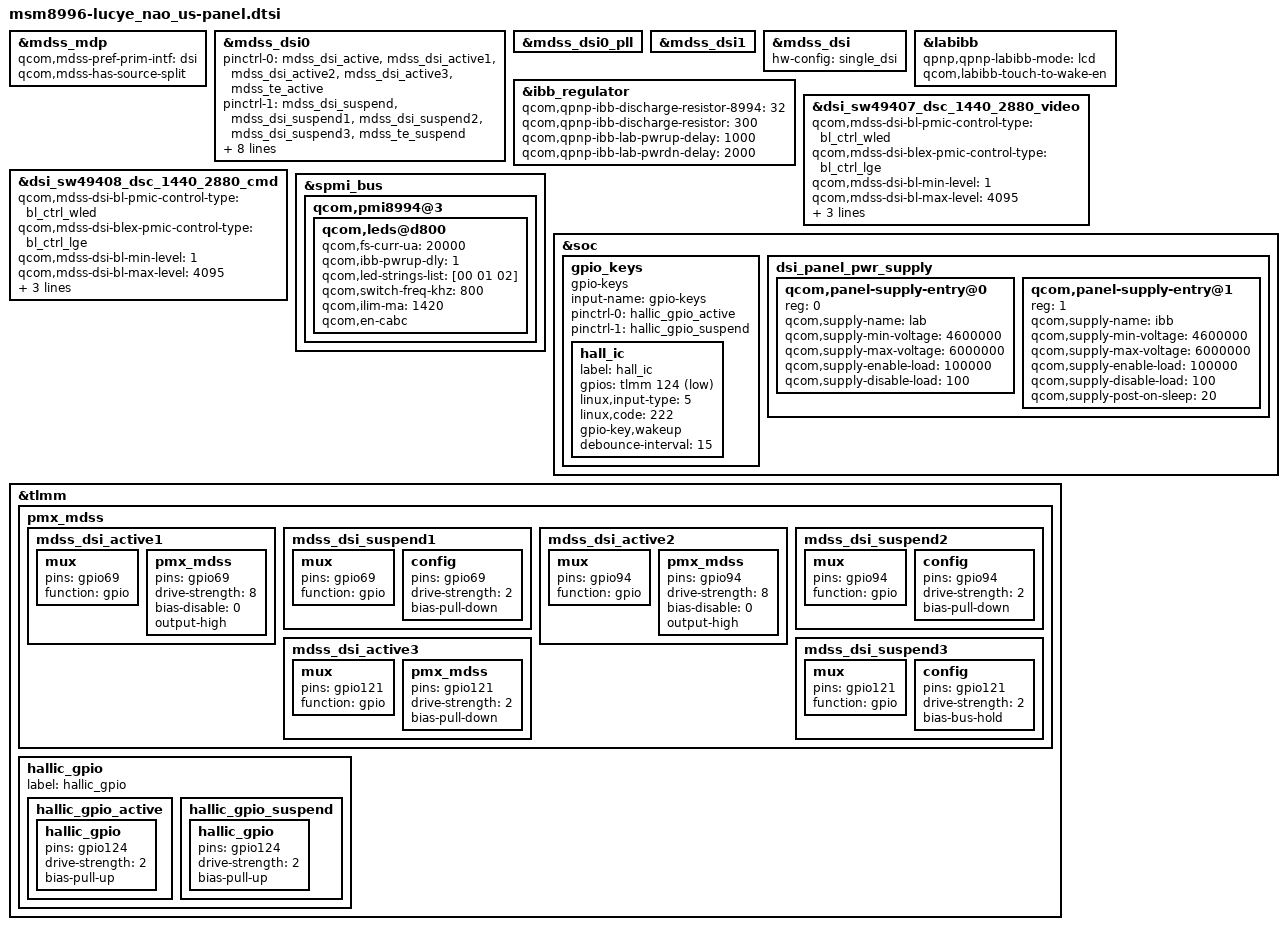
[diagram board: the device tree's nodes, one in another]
/* Copyright (c) 2015, The Linux Foundation. All rights reserved.
 *
 * This program is free software; you can redistribute it and/or modify
 * it under the terms of the GNU General Public License version 2 and
 * only version 2 as published by the Free Software Foundation.
 *
 * This program is distributed in the hope that it will be useful,
 * but WITHOUT ANY WARRANTY; without even the implied warranty of
 * MERCHANTABILITY or FITNESS FOR A PARTICULAR PURPOSE.  See the
 * GNU General Public License for more details.
 */

#include "../dsi-panel-sw49407-dsc-1440-2880-video.dtsi"
#include "../dsi-panel-sw49408-dsc-1440-2880-cmd.dtsi"

&mdss_mdp {
	qcom,mdss-pref-prim-intf = "dsi";
	qcom,mdss-has-source-split;
};

&mdss_dsi0 {
	pinctrl-names = "mdss_default", "mdss_sleep";
	pinctrl-0 = <&mdss_dsi_active &mdss_dsi_active1 &mdss_dsi_active2 &mdss_dsi_active3 &mdss_te_active>;
	pinctrl-1 = <&mdss_dsi_suspend &mdss_dsi_suspend1 &mdss_dsi_suspend2 &mdss_dsi_suspend3 &mdss_te_suspend>;
	qcom,dsi-panel-bias-vreg;
	qcom,platform-te-gpio = <&tlmm 10 0>;
	qcom,platform-reset-gpio = <&tlmm 8 0>;

	/delete-property/vddio-supply;

	qcom,dsi-pref-prim-pan = <&dsi_sw49408_dsc_1440_2880_cmd>;
	lge,extra-gpio-names = "vddio", "vpnl";

	lge,gpio-vddio = <&tlmm 69 0>;
	lge,gpio-vpnl = <&tlmm 94 0>;
};

&mdss_dsi0_pll {
		/delete-property/ memory-region;
};

&mdss_dsi1 {
	/delete-property/cell-index;
};

&mdss_dsi {
	hw-config = "single_dsi";
};

&labibb {
	status = "ok";
	qpnp,qpnp-labibb-mode = "lcd";
	qcom,labibb-touch-to-wake-en;
};

&ibb_regulator {
	qcom,qpnp-ibb-discharge-resistor-8994 = <32>;
	qcom,qpnp-ibb-discharge-resistor = <300>;
	qcom,qpnp-ibb-lab-pwrup-delay = <1000>;
	qcom,qpnp-ibb-lab-pwrdn-delay = <2000>;
};

&dsi_sw49407_dsc_1440_2880_video {
	qcom,mdss-dsi-bl-pmic-control-type = "bl_ctrl_wled";
	qcom,mdss-dsi-blex-pmic-control-type = "bl_ctrl_lge";
	qcom,mdss-dsi-bl-min-level = <1>;
	qcom,mdss-dsi-bl-max-level = <4095>;
	qcom,cont-splash-enabled;
	qcom,panel-supply-entries = <&dsi_panel_pwr_supply>;
};

&dsi_sw49408_dsc_1440_2880_cmd {
	qcom,mdss-dsi-bl-pmic-control-type = "bl_ctrl_wled";
	qcom,mdss-dsi-blex-pmic-control-type = "bl_ctrl_lge";
	qcom,mdss-dsi-bl-min-level = <1>;
	qcom,mdss-dsi-bl-max-level = <4095>;
	qcom,cont-splash-enabled;
	qcom,panel-supply-entries = <&dsi_panel_pwr_supply>;
};

&spmi_bus {
	qcom,pmi8994@3 {
		qcom,leds@d800 {
			qcom,fs-curr-ua = <20000>;
			qcom,ibb-pwrup-dly = <1>;
			qcom,led-strings-list = [00 01 02];
			qcom,switch-freq-khz = <800>;
			qcom,ilim-ma = <1420>;
			qcom,en-cabc;
		};
	};
};

&soc {
	gpio_keys {
		compatible = "gpio-keys";
		input-name = "gpio-keys";

		pinctrl-names = "tlmm_gpio_key_active","tlmm_gpio_key_suspend";
		pinctrl-0 = <&hallic_gpio_active>;
		pinctrl-1 = <&hallic_gpio_suspend>;

		hall_ic {
			label = "hall_ic";
			gpios = <&tlmm 124 0x1>;
			linux,input-type = <5>;
			linux,code = <222>;
			gpio-key,wakeup;
			debounce-interval = <15>;
		};
	};

	dsi_panel_pwr_supply: dsi_panel_pwr_supply {
		#address-cells = <1>;
		#size-cells = <0>;

		qcom,panel-supply-entry@0 {
			reg = <0>;
			qcom,supply-name = "lab";
			qcom,supply-min-voltage = <4600000>;
			qcom,supply-max-voltage = <6000000>;
			qcom,supply-enable-load = <100000>;
			qcom,supply-disable-load = <100>;
		};

		qcom,panel-supply-entry@1 {
			reg = <1>;
			qcom,supply-name = "ibb";
			qcom,supply-min-voltage = <4600000>;
			qcom,supply-max-voltage = <6000000>;
			qcom,supply-enable-load = <100000>;
			qcom,supply-disable-load = <100>;
			qcom,supply-post-on-sleep = <20>;
		};
	};
};

&tlmm {
  pmx_mdss: pmx_mdss {

    /* GPIO_69 : LCD_VDD_IO_EN */
    mdss_dsi_active1: mdss_dsi_active1 {
      mux {
        pins = "gpio69";
        function = "gpio";
      };

      pmx_mdss {
        pins = "gpio69";
        drive-strength = <8>; /* 8 mA */
        bias-disable = <0>; /* no pull */
        output-high;
      };
    };
    mdss_dsi_suspend1: mdss_dsi_suspend1 {
      mux {
        pins = "gpio69";
        function = "gpio";
      };

      config {
        pins = "gpio69";
        drive-strength = <2>; /* 2 mA */
        bias-pull-down; /* pull down */
      };
    };

    /* GPIO_94 : LCD_VCL_EN */
    mdss_dsi_active2: mdss_dsi_active2 {
      mux {
        pins = "gpio94";
        function = "gpio";
      };

      pmx_mdss {
        pins = "gpio94";
        drive-strength = <8>; /* 8 mA */
        bias-disable = <0>; /* no pull */
        output-high;
      };
    };
    mdss_dsi_suspend2: mdss_dsi_suspend2 {
      mux {
        pins = "gpio94";
        function = "gpio";
      };

      config {
        pins = "gpio94";
        drive-strength = <2>; /* 2 mA */
        bias-pull-down; /* pull down */
      };
    };

    /* GPIO_121 */
    mdss_dsi_active3: mdss_dsi_active3 {
      mux {
        pins = "gpio121";
        function = "gpio";
      };

      pmx_mdss {
        pins = "gpio121";
        drive-strength = <2>; /* 2 mA */
        bias-pull-down;  /* pull down */
      };
    };
    mdss_dsi_suspend3: mdss_dsi_suspend3 {
      mux {
        pins = "gpio121";
        function = "gpio";
      };

      config {
        pins = "gpio121";
        drive-strength = <2>; /* 2 mA */
        bias-bus-hold;
      };
    };
  };

  /* GPIO_124 : HALLIC */
  hallic_gpio {
    label = "hallic_gpio";
    hallic_gpio_active: hallic_gpio_active {
      hallic_gpio {
        pins = "gpio124";
        drive-strength = <2>;
        bias-pull-up;
      };
    };
    hallic_gpio_suspend: hallic_gpio_suspend {
      hallic_gpio {
        pins = "gpio124";
        drive-strength = <2>;
        bias-pull-up;
      };
    };
  };
};
